AUTOSAR XML (schema 4-3-0)
standard types defined: Boolean, UInt16, UInt32, UInt8, boolean, uint16, uint32, uint8
package /DataTypes
  impl type SGaugeInfo_u32dyn_3: category=ARRAY, sw-calibration-access=READ-ONLY, type-emitter=RTE
    element Element: array-size=3, array-size-semantics=FIXED-SIZE, implementation-data-type=SGaugeInfo_u32dyn
package /E40_Platform_System_SystemPackage/Components
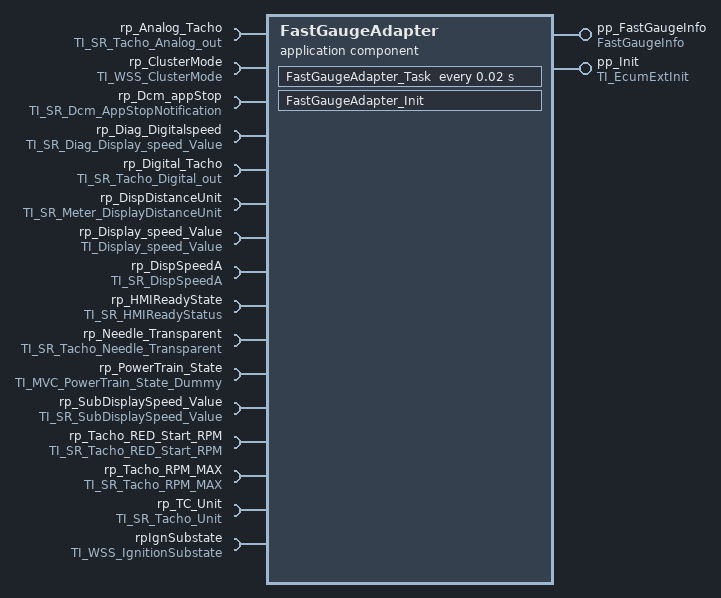
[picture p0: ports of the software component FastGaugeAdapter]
  application sw component type FastGaugeAdapter
    provide port pp_FastGaugeInfo: nonqueued-sender-com-spec{data-element=FastGaugeInfoData, init-value=constant-reference=FastGaugeAdapterFastGaugeInfoDataValue0}, provided-interface=FastGaugeInfo
    provide port pp_Init: server-com-spec{operation=Init, queue-length=1}, provided-interface=TI_EcumExtInit
    16 x require port:
      rp_Analog_Tacho: nonqueued-receiver-com-spec{data-element=Analog_Tacho, filter=data-filter-type=ALWAYS, init-value=constant-reference=FastGaugeAdapterAnalog_TachoValue0}, required-interface=TI_SR_Tacho_Analog_out
      rp_ClusterMode: nonqueued-receiver-com-spec{data-element=WSSCurrentClusterMode, filter=data-filter-type=ALWAYS, init-value=constant-reference=FastGaugeAdapterWSSCurrentClusterModeValue0}, required-interface=TI_WSS_ClusterMode
      rp_Dcm_appStop: nonqueued-receiver-com-spec{data-element=AppId, filter=data-filter-type=ALWAYS, init-value=constant-reference=FastGaugeAdapterAppIdValue0}, required-interface=TI_SR_Dcm_AppStopNotification
      rp_Diag_Digitalspeed: nonqueued-receiver-com-spec{data-element=Diag_Digital_Speed_Value, filter=data-filter-type=ALWAYS, init-value=constant-reference=FastGaugeAdapterDiag_Digital_Speed_ValueValue0}, required-interface=TI_SR_Diag_Display_speed_Value
      rp_Digital_Tacho: nonqueued-receiver-com-spec{data-element=Digital_Tacho, filter=data-filter-type=ALWAYS, init-value=constant-reference=FastGaugeAdapterDigital_TachoValue0}, required-interface=TI_SR_Tacho_Digital_out
      rp_DispDistanceUnit: nonqueued-receiver-com-spec{data-element=DisplayUnit, filter=data-filter-type=ALWAYS, init-value=constant-reference=FastGaugeAdapterDisplayUnitValue0}, required-interface=TI_SR_Meter_DisplayDistanceUnit
      rp_Display_speed_Value: nonqueued-receiver-com-spec{data-element=Digital_Speed_Value, filter=data-filter-type=ALWAYS, init-value=constant-reference=FastGaugeAdapterDigital_Speed_ValueValue0}, required-interface=TI_Display_speed_Value
      rp_DispSpeedA: nonqueued-receiver-com-spec{data-element=DispSpeedVal, filter=data-filter-type=ALWAYS, init-value=constant-reference=FastGaugeAdapterDispSpeedValValue0}, required-interface=TI_SR_DispSpeedA
      rp_HMIReadyState: nonqueued-receiver-com-spec{data-element=HMI_ReadyStatus, filter=data-filter-type=ALWAYS, init-value=constant-reference=FastGaugeAdapterHMI_ReadyStatusValue0}, required-interface=TI_SR_HMIReadyStatus
      rp_Needle_Transparent: nonqueued-receiver-com-spec{data-element=Needle_TR, filter=data-filter-type=ALWAYS, init-value=constant-reference=FastGaugeAdapterNeedle_TRValue0}, required-interface=TI_SR_Tacho_Needle_Transparent
      rp_PowerTrain_State: nonqueued-receiver-com-spec{data-element=PowerTrain_Flag, filter=data-filter-type=ALWAYS, init-value=constant-reference=FastGaugeAdapterPowerTrain_FlagValue0}, required-interface=TI_MVC_PowerTrain_State_Dummy
      rp_SubDisplaySpeed_Value: nonqueued-receiver-com-spec{data-element=SubDispSpeedVal, filter=data-filter-type=ALWAYS, init-value=constant-reference=FastGaugeAdapterSubDispSpeedValValue0}, required-interface=TI_SR_SubDisplaySpeed_Value
      rp_Tacho_RED_Start_RPM: nonqueued-receiver-com-spec{data-element=RED_Start_RPM, filter=data-filter-type=ALWAYS, init-value=constant-reference=FastGaugeAdapterRED_Start_RPMValue0}, required-interface=TI_SR_Tacho_RED_Start_RPM
      rp_Tacho_RPM_MAX: nonqueued-receiver-com-spec{data-element=REVP_RPM_MAX, filter=data-filter-type=ALWAYS, init-value=constant-reference=FastGaugeAdapterREVP_RPM_MAXValue0}, required-interface=TI_SR_Tacho_RPM_MAX
      rp_TC_Unit: nonqueued-receiver-com-spec{data-element=Digital_TachoUnit, filter=data-filter-type=ALWAYS, init-value=constant-reference=FastGaugeAdapterDigital_TachoUnitValue0}, required-interface=TI_SR_Tacho_Unit
      rpIgnSubstate: nonqueued-receiver-com-spec{data-element=IgnitionSubstate, filter=data-filter-type=ALWAYS, init-value=constant-reference=FastGaugeAdapterIgnitionSubstateValue0}, required-interface=TI_WSS_IgnitionSubstate
    behavior IB_FastGaugeAdapter
      operation invoked event OIE_pp_Init_FastGaugeAdapter_InitTrigByInit: start-on-event=FastGaugeAdapter_Init, operation=pp_Init.Init
      timing event TEFastGaugeAdapter_Task: start-on-event=FastGaugeAdapter_Task, period=0.02
      port-api-options:
        enable-take-address=false, error-handling=NO-TRANSFORMER-ERROR-HANDLING, indirect-api=false, port=pp_FastGaugeInfo
        enable-take-address=false, error-handling=NO-TRANSFORMER-ERROR-HANDLING, indirect-api=false, port=pp_Init
        enable-take-address=false, error-handling=NO-TRANSFORMER-ERROR-HANDLING, indirect-api=false, port=rp_Analog_Tacho
        enable-take-address=false, error-handling=NO-TRANSFORMER-ERROR-HANDLING, indirect-api=false, port=rp_ClusterMode
        enable-take-address=false, error-handling=NO-TRANSFORMER-ERROR-HANDLING, indirect-api=false, port=rp_Dcm_appStop
        enable-take-address=false, error-handling=NO-TRANSFORMER-ERROR-HANDLING, indirect-api=false, port=rp_Diag_Digitalspeed
        enable-take-address=false, error-handling=NO-TRANSFORMER-ERROR-HANDLING, indirect-api=false, port=rp_Digital_Tacho
        enable-take-address=false, error-handling=NO-TRANSFORMER-ERROR-HANDLING, indirect-api=false, port=rp_DispDistanceUnit
        enable-take-address=false, error-handling=NO-TRANSFORMER-ERROR-HANDLING, indirect-api=false, port=rp_Display_speed_Value
        enable-take-address=false, error-handling=NO-TRANSFORMER-ERROR-HANDLING, indirect-api=false, port=rp_DispSpeedA
        enable-take-address=false, error-handling=NO-TRANSFORMER-ERROR-HANDLING, indirect-api=false, port=rp_HMIReadyState
        enable-take-address=false, error-handling=NO-TRANSFORMER-ERROR-HANDLING, indirect-api=false, port=rp_Needle_Transparent
        enable-take-address=false, error-handling=NO-TRANSFORMER-ERROR-HANDLING, indirect-api=false, port=rp_PowerTrain_State
        enable-take-address=false, error-handling=NO-TRANSFORMER-ERROR-HANDLING, indirect-api=false, port=rp_SubDisplaySpeed_Value
        enable-take-address=false, error-handling=NO-TRANSFORMER-ERROR-HANDLING, indirect-api=false, port=rp_Tacho_RED_Start_RPM
        enable-take-address=false, error-handling=NO-TRANSFORMER-ERROR-HANDLING, indirect-api=false, port=rp_Tacho_RPM_MAX
        enable-take-address=false, error-handling=NO-TRANSFORMER-ERROR-HANDLING, indirect-api=false, port=rp_TC_Unit
        enable-take-address=false, error-handling=NO-TRANSFORMER-ERROR-HANDLING, indirect-api=false, port=rpIgnSubstate
      runnable FastGaugeAdapter_Init: can-be-invoked-concurrently=true
      runnable FastGaugeAdapter_Task: can-be-invoked-concurrently=true
        data-receive-point-by-arguments:
          16 x access:
            DRA_rp_Analog_Tacho_Analog_Tacho: accessed-variable=rp_Analog_Tacho.Analog_Tacho
            DRA_rp_ClusterMode_WSSCurrentClusterMode: accessed-variable=rp_ClusterMode.WSSCurrentClusterMode
            DRA_rp_Dcm_appStop_AppId: accessed-variable=rp_Dcm_appStop.AppId
            DRA_rp_Diag_Digitalspeed_Diag_Digital_Speed_Value: accessed-variable=rp_Diag_Digitalspeed.Diag_Digital_Speed_Value
            DRA_rp_Digital_Tacho_Digital_Tacho: accessed-variable=rp_Digital_Tacho.Digital_Tacho
            DRA_rp_DispDistanceUnit_DisplayUnit: accessed-variable=rp_DispDistanceUnit.DisplayUnit
            DRA_rp_Display_speed_Value_Digital_Speed_Value: accessed-variable=rp_Display_speed_Value.Digital_Speed_Value
            DRA_rp_DispSpeedA_DispSpeedVal: accessed-variable=rp_DispSpeedA.DispSpeedVal
            DRA_rp_HMIReadyState_HMI_ReadyStatus: accessed-variable=rp_HMIReadyState.HMI_ReadyStatus
            DRA_rp_Needle_Transparent_Needle_TR: accessed-variable=rp_Needle_Transparent.Needle_TR
            DRA_rp_PowerTrain_State_PowerTrain_Flag: accessed-variable=rp_PowerTrain_State.PowerTrain_Flag
            DRA_rp_SubDisplaySpeed_Value_SubDispSpeedVal: accessed-variable=rp_SubDisplaySpeed_Value.SubDispSpeedVal
            DRA_rp_Tacho_RED_Start_RPM_RED_Start_RPM: accessed-variable=rp_Tacho_RED_Start_RPM.RED_Start_RPM
            DRA_rp_Tacho_RPM_MAX_REVP_RPM_MAX: accessed-variable=rp_Tacho_RPM_MAX.REVP_RPM_MAX
            DRA_rp_TC_Unit_Digital_TachoUnit: accessed-variable=rp_TC_Unit.Digital_TachoUnit
            DRA_rpIgnSubstate_IgnitionSubstate: accessed-variable=rpIgnSubstate.IgnitionSubstate
        data-send-points:
          access DWA_pp_FastGaugeInfo_FastGaugeInfoData: accessed-variable=pp_FastGaugeInfo.FastGaugeInfoData
  17 x constant specification:
    FastGaugeAdapterAnalog_TachoValue0: value-spec=FastGaugeAdapterAnalog_TachoValue0:0
    FastGaugeAdapterAppIdValue0: value-spec=FastGaugeAdapterAppIdValue0:0
    FastGaugeAdapterDiag_Digital_Speed_ValueValue0: value-spec=FastGaugeAdapterDiag_Digital_Speed_ValueValue0:0
    FastGaugeAdapterDigital_Speed_ValueValue0: value-spec=FastGaugeAdapterDigital_Speed_ValueValue0:0
    FastGaugeAdapterDigital_TachoUnitValue0: value-spec=FastGaugeAdapterDigital_TachoUnitValue0:false
    FastGaugeAdapterDigital_TachoValue0: value-spec=FastGaugeAdapterDigital_TachoValue0:0
    FastGaugeAdapterDisplayUnitValue0: value-spec=FastGaugeAdapterDisplayUnitValue0:0
    FastGaugeAdapterDispSpeedValValue0: value-spec=FastGaugeAdapterDispSpeedValValue0:0
    FastGaugeAdapterFastGaugeInfoDataValue0: value-spec={short-label=FastGaugeAdapterFastGaugeInfoDataValue0, fields=gaugeInfo:[fields=[id:0, position:0, digitalData:0, unit:0, dynData:0], fields=[id:0, position:0, digitalData:0, unit:0, dynData:0], fields=[id:0, position:0, digitalData:0, unit:0, dynData:0]]}
    FastGaugeAdapterHMI_ReadyStatusValue0: value-spec=FastGaugeAdapterHMI_ReadyStatusValue0:0
    FastGaugeAdapterIgnitionSubstateValue0: value-spec=FastGaugeAdapterIgnitionSubstateValue0:0
    FastGaugeAdapterNeedle_TRValue0: value-spec=FastGaugeAdapterNeedle_TRValue0:0
    FastGaugeAdapterPowerTrain_FlagValue0: value-spec=FastGaugeAdapterPowerTrain_FlagValue0:0
    FastGaugeAdapterRED_Start_RPMValue0: value-spec=FastGaugeAdapterRED_Start_RPMValue0:0
    FastGaugeAdapterREVP_RPM_MAXValue0: value-spec=FastGaugeAdapterREVP_RPM_MAXValue0:0
    FastGaugeAdapterSubDispSpeedValValue0: value-spec=FastGaugeAdapterSubDispSpeedValValue0:0
    FastGaugeAdapterWSSCurrentClusterModeValue0: value-spec=FastGaugeAdapterWSSCurrentClusterModeValue0:0
  swc implementation IMPL_FastGaugeAdapter: behavior=IB_FastGaugeAdapter
    code-descriptors:
      code Default: artifact-descriptors=autosar-engineering-object={short-label=Default, category=SWSRC}
package /E40_Platform_System_SystemPackage/Types
  client server interface TI_EcumExtInit
    operation Init
  7 x impl type:
    ClusterModes: category=VALUE, base-type=uint8, compu {0=CLUSTER_INACTIVE, 1=CLUSTER_ACTIVE}, range raw 0..1
    EGaugeUnit: category=VALUE, base-type=uint8, compu {0=EGaugeUnit_Mph, 1=EGaugeUnit_Kmph, 2=EGaugeUnit_Centigrade, 3=EGaugeUnit_Farenheit, 4=EGaugeUnit_Psi, 5=EGaugeUnit_Pa, 6=EGaugeUnit_Bar, 7=EGaugeUnit_Kmpl, 8=EGaugeUnit_Mpg, 9=EGaugeUnit_Ltr, 10=EGaugeUnit_Gal, 11=EGaugeUnit_Km, 12=EGaugeUnit_Mile, 13=EGaugeUnit_Last}, range raw 0..13
    HMIReadySts_Type: category=VALUE, base-type=uint8, compu {0=eHMI_NOT_READY, 1=eHMI_READY}, range raw 0..1
    IgntionSubstateType: category=VALUE, base-type=uint8, compu {0=IgnOff, 1=IgnOn}, range raw 0..1
    IOCtrl_Type: category=VALUE, base-type=uint8, compu {1=eSPEEDO, 2=eTACHO, 4=eHVSYS_INDICATOR, 8=eSPEAKER, 16=eTELLTALE, 32=eBUTTONEVENT, 64=eMIDDISPALY}, range raw 1..64
    SFastGaugeInfo: category=STRUCTURE
      element gaugeInfo: implementation-data-type=SGaugeInfo_u32dyn_3
    SGaugeInfo_u32dyn: category=STRUCTURE
      5 x element, all with category=TYPE_REFERENCE:
        id: implementation-data-type=UInt8
        position: implementation-data-type=UInt16
        digitalData: implementation-data-type=UInt32
        unit: implementation-data-type=EGaugeUnit
        dynData: implementation-data-type=UInt16
  17 x sender receiver interface:
    FastGaugeInfo: invalidation-policy{data-element=FastGaugeInfoData, handle-invalid=DONT-INVALIDATE}
      data FastGaugeInfoData: type=SFastGaugeInfo
    TI_Display_speed_Value: invalidation-policy{data-element=Digital_Speed_Value, handle-invalid=DONT-INVALIDATE}
      data Digital_Speed_Value: type=UInt16
    TI_MVC_PowerTrain_State_Dummy: invalidation-policy{data-element=PowerTrain_Flag, handle-invalid=DONT-INVALIDATE}
      data PowerTrain_Flag: type=UInt8
    TI_SR_Dcm_AppStopNotification: invalidation-policy{data-element=AppId, handle-invalid=DONT-INVALIDATE}
      data AppId: type=IOCtrl_Type
    TI_SR_Diag_Display_speed_Value: invalidation-policy{data-element=Diag_Digital_Speed_Value, handle-invalid=DONT-INVALIDATE}
      data Diag_Digital_Speed_Value: type=UInt16
    TI_SR_DispSpeedA: invalidation-policy{data-element=DispSpeedVal, handle-invalid=DONT-INVALIDATE}
      data DispSpeedVal: type=UInt16
    TI_SR_HMIReadyStatus: invalidation-policy{data-element=HMI_ReadyStatus, handle-invalid=DONT-INVALIDATE}
      data HMI_ReadyStatus: type=HMIReadySts_Type
    TI_SR_Meter_DisplayDistanceUnit: invalidation-policy{data-element=DisplayUnit, handle-invalid=DONT-INVALIDATE}
      data DisplayUnit: type=UInt8
    TI_SR_SubDisplaySpeed_Value: invalidation-policy{data-element=SubDispSpeedVal, handle-invalid=DONT-INVALIDATE}
      data SubDispSpeedVal: type=UInt16
    TI_SR_Tacho_Analog_out: invalidation-policy{data-element=Analog_Tacho, handle-invalid=DONT-INVALIDATE}
      data Analog_Tacho: type=UInt16
    TI_SR_Tacho_Digital_out: invalidation-policy{data-element=Digital_Tacho, handle-invalid=DONT-INVALIDATE}
      data Digital_Tacho: type=UInt16
    TI_SR_Tacho_Needle_Transparent: invalidation-policy{data-element=Needle_TR, handle-invalid=DONT-INVALIDATE}
      data Needle_TR: type=UInt8
    TI_SR_Tacho_RED_Start_RPM: invalidation-policy{data-element=RED_Start_RPM, handle-invalid=DONT-INVALIDATE}
      data RED_Start_RPM: type=UInt8
    TI_SR_Tacho_RPM_MAX: invalidation-policy{data-element=REVP_RPM_MAX, handle-invalid=DONT-INVALIDATE}
      data REVP_RPM_MAX: type=UInt8
    TI_SR_Tacho_Unit: invalidation-policy{data-element=Digital_TachoUnit, handle-invalid=DONT-INVALIDATE}
      data Digital_TachoUnit: type=Boolean
    TI_WSS_ClusterMode: invalidation-policy{data-element=WSSCurrentClusterMode, handle-invalid=DONT-INVALIDATE}
      data WSSCurrentClusterMode: type=ClusterModes
    TI_WSS_IgnitionSubstate: invalidation-policy{data-element=IgnitionSubstate, handle-invalid=DONT-INVALIDATE}
      data IgnitionSubstate: type=IgntionSubstateType
package /E40_Platform_System_SystemPackage/Types/DataConstrs
  range Boolean_DataConstraint: raw 0..1
  range UInt16_DataConstraint: raw 0..65535
  range UInt32_DataConstraint: raw 0..4294967295
  range UInt8_DataConstraint: raw 0..255
